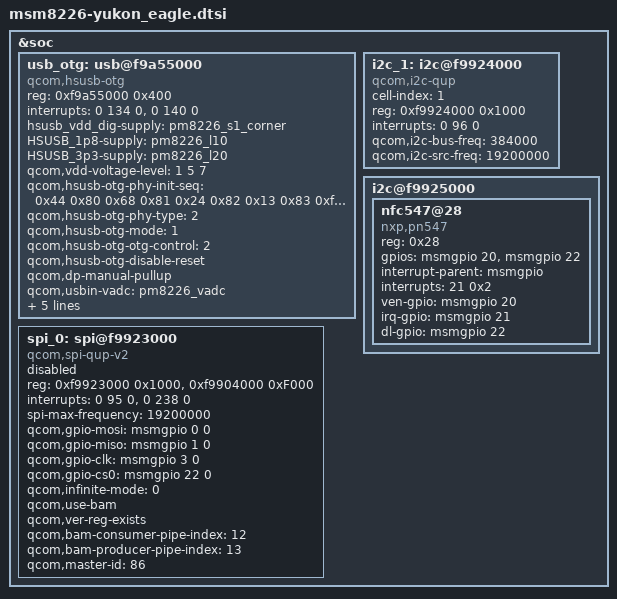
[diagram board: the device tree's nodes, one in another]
/* Copyright (c) 2012-2013, The Linux Foundation. All rights reserved.
 * Copyright (c) 2013 Sony Mobile Communications AB.
 *
 * This program is free software; you can redistribute it and/or modify
 * it under the terms of the GNU General Public License version 2 and
 * only version 2 as published by the Free Software Foundation.
 *
 * This program is distributed in the hope that it will be useful,
 * but WITHOUT ANY WARRANTY; without even the implied warranty of
 * MERCHANTABILITY or FITNESS FOR A PARTICULAR PURPOSE.  See the
 * GNU General Public License for more details.
 */

/include/ "msm8226.dtsi"
/include/ "msm-yukon_eagle-pm8226.dtsi"
/include/ "msm8226-yukon_eagle-regulator.dtsi"

&soc {
        usb_otg: usb@f9a55000 {
                compatible = "qcom,hsusb-otg";
                reg = <0xf9a55000 0x400>;
                interrupts = <0 134 0>, <0 140 0>;
                interrupt-names = "core_irq", "async_irq";
                hsusb_vdd_dig-supply = <&pm8226_s1_corner>;
                HSUSB_1p8-supply = <&pm8226_l10>;
                HSUSB_3p3-supply = <&pm8226_l20>;
                qcom,vdd-voltage-level = <1 5 7>;

                qcom,hsusb-otg-phy-init-seq =
                        <0x44 0x80 0x68 0x81 0x24 0x82 0x13 0x83 0xffffffff>;
                qcom,hsusb-otg-phy-type = <2>;
                qcom,hsusb-otg-mode = <1>;
                qcom,hsusb-otg-otg-control = <2>;
		qcom,hsusb-otg-disable-reset;
                qcom,dp-manual-pullup;
                qcom,usbin-vadc = <&pm8226_vadc>;

                qcom,msm-bus,name = "usb";
                qcom,msm-bus,num-cases = <3>;
                qcom,msm-bus,num-paths = <1>;
                qcom,msm-bus,vectors-KBps =
                                <87 512 0 0>,
                                <87 512 60000 960000>,
                                <87 512 6000  6000>;
        };

        i2c_1: i2c@f9924000 { /* BLSP-1 QUP-2 */
                cell-index = <1>;
                compatible = "qcom,i2c-qup";
                reg = <0xf9924000 0x1000>;
                #address-cells = <1>;
                #size-cells = <0>;
                reg-names = "qup_phys_addr";
                interrupts = <0 96 0>;
                interrupt-names = "qup_err_intr";
                qcom,i2c-bus-freq = <384000>;
                qcom,i2c-src-freq = <19200000>;
        };


       i2c@f9925000 { /* BLSP-1 QUP-3 */
       nfc547@28 {
                        compatible = "nxp,pn547";
                        reg = <0x28>;
                        gpios = <&msmgpio 20 0>, <&msmgpio 22>;
                        interrupt-parent = <&msmgpio> ;
                        interrupts = <21 0x2>;
                        ven-gpio = <&msmgpio 20 0x00>;
                        irq-gpio = <&msmgpio 21 0x00>;
                        dl-gpio = <&msmgpio 22 0x00>;

                };
       };

        spi_0: spi@f9923000 { /* BLSP1 QUP1 */
                compatible = "qcom,spi-qup-v2";
                #address-cells = <1>;
                #size-cells = <0>;
                reg-names = "spi_physical", "spi_bam_physical";
                reg = <0xf9923000 0x1000>,
                      <0xf9904000 0xF000>;
                interrupt-names = "spi_irq", "spi_bam_irq";
                interrupts = <0 95 0>, <0 238 0>;
                spi-max-frequency = <19200000>;

                qcom,gpio-mosi = <&msmgpio 0 0>;
                qcom,gpio-miso = <&msmgpio 1 0>;
                qcom,gpio-clk  = <&msmgpio 3 0>;
                qcom,gpio-cs0  = <&msmgpio 22 0>;

                qcom,infinite-mode = <0>;
                qcom,use-bam;
                qcom,ver-reg-exists;
                qcom,bam-consumer-pipe-index = <12>;
                qcom,bam-producer-pipe-index = <13>;
                qcom,master-id = <86>;
		status = "disabled";
        };
};
